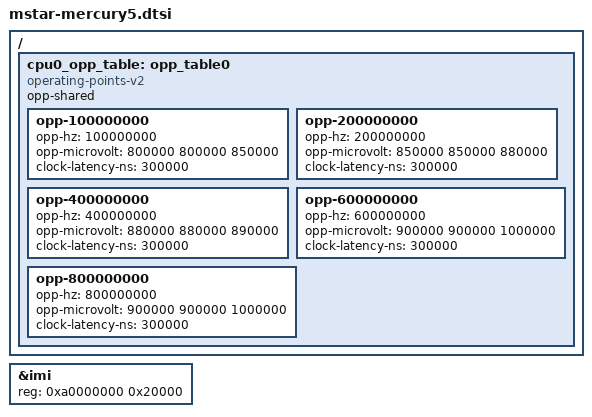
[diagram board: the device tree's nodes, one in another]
// SPDX-License-Identifier: GPL-2.0-or-later
/*
 * Copyright (c) 2020 thingy.jp.
 * Author: Daniel Palmer <daniel@thingy.jp>
 */

#include "mstar-v7.dtsi"

/ {
	cpu0_opp_table: opp_table0 {
		compatible = "operating-points-v2";
		opp-shared;

		opp-100000000 {
			opp-hz = /bits/ 64 <100000000>;
			opp-microvolt = <800000 800000 850000>;
			clock-latency-ns = <300000>;
		};

		opp-200000000 {
			opp-hz = /bits/ 64 <200000000>;
			opp-microvolt = <850000 850000 880000>;
			clock-latency-ns = <300000>;
		};

		opp-400000000 {
			opp-hz = /bits/ 64 <400000000>;
			opp-microvolt = <880000 880000 890000>;
			clock-latency-ns = <300000>;
		};
		opp-600000000 {
			opp-hz = /bits/ 64 <600000000>;
			opp-microvolt = <900000 900000 1000000>;
			clock-latency-ns = <300000>;
		};

		opp-800000000 {
			opp-hz = /bits/ 64 <800000000>;
			opp-microvolt = <900000 900000 1000000>;
			clock-latency-ns = <300000>;
		};
	};
};

&imi {
	reg = <0xa0000000 0x20000>;
};
